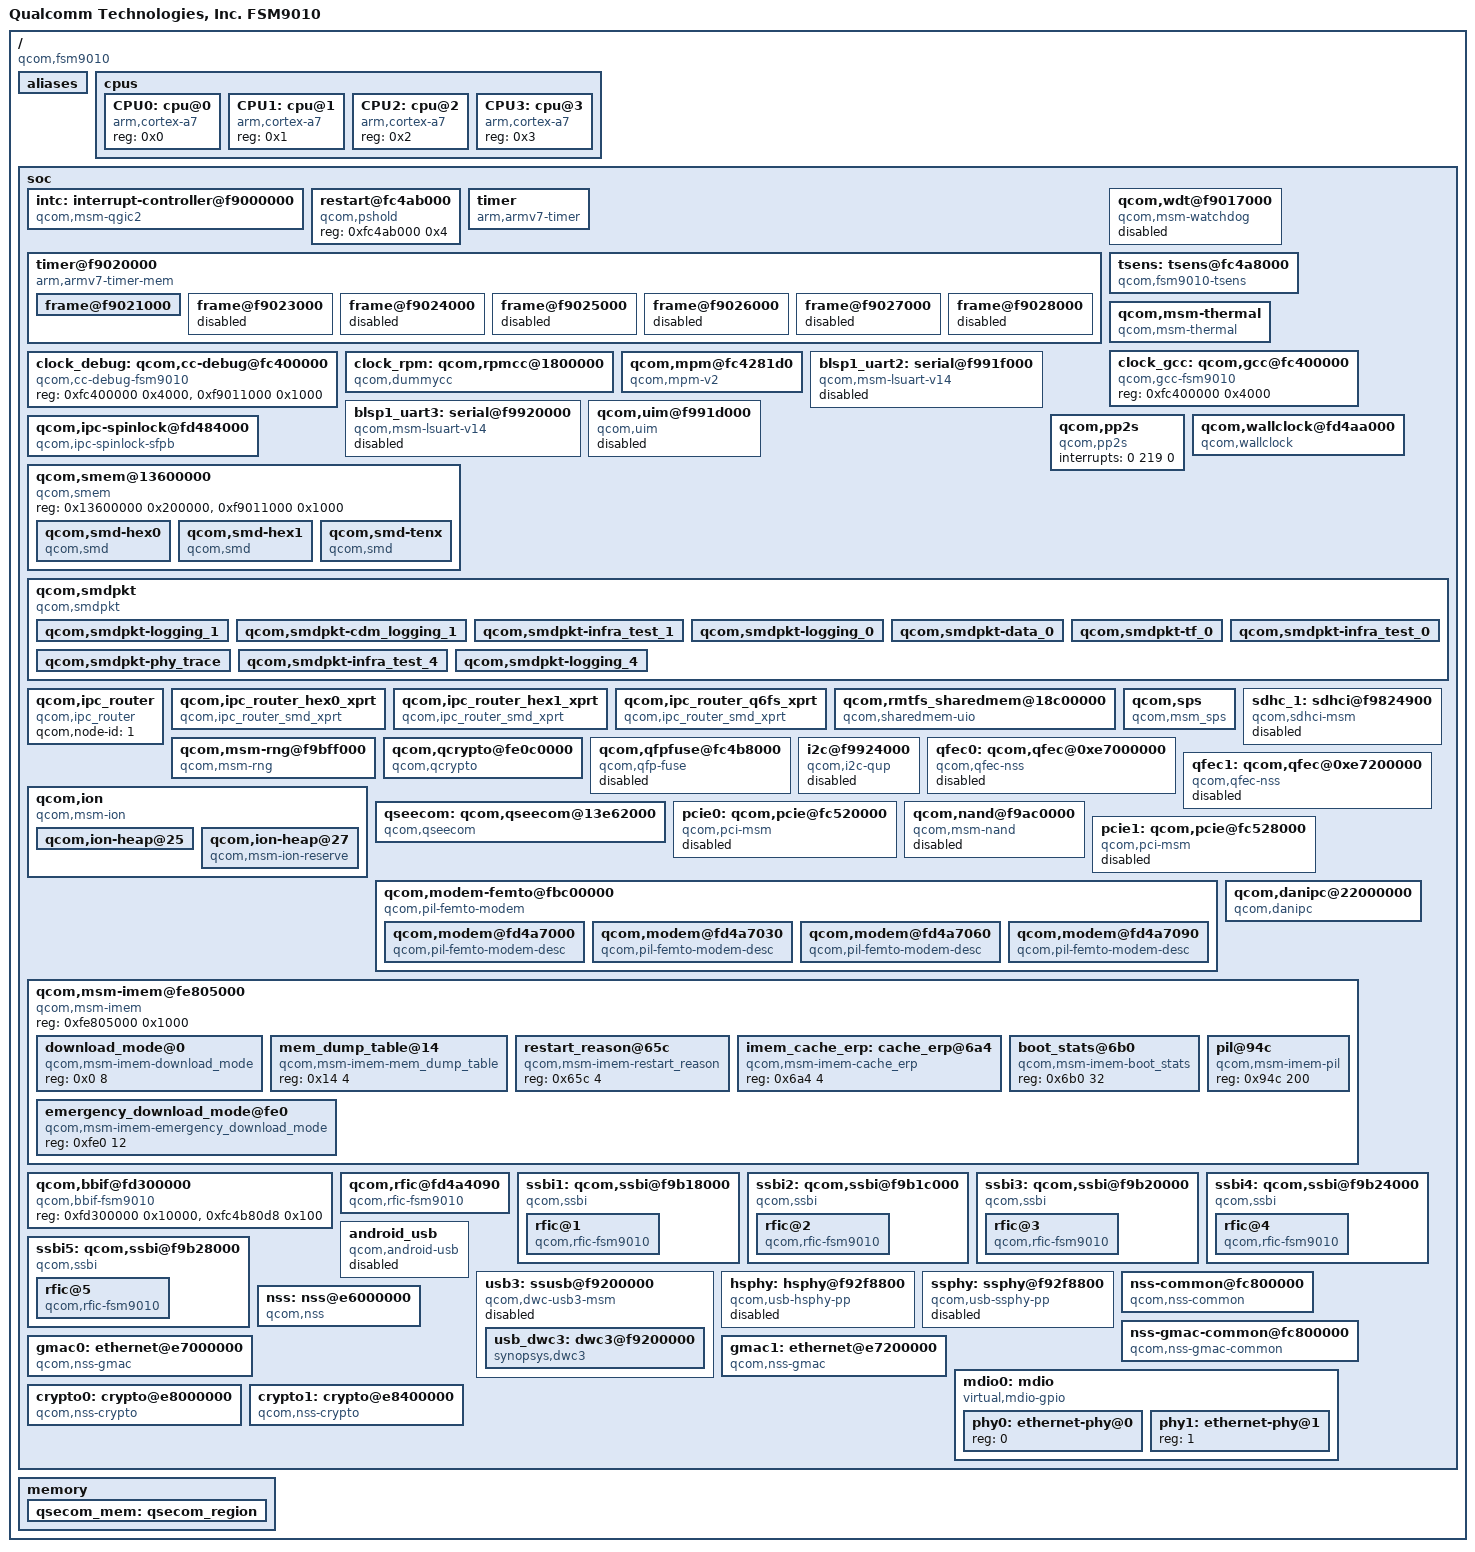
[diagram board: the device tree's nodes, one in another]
/* Copyright (c) 2014-2015, The Linux Foundation. All rights reserved.
 *
 * This program is free software; you can redistribute it and/or modify
 * it under the terms of the GNU General Public License version 2 and
 * only version 2 as published by the Free Software Foundation.
 *
 * This program is distributed in the hope that it will be useful,
 * but WITHOUT ANY WARRANTY; without even the implied warranty of
 * MERCHANTABILITY or FITNESS FOR A PARTICULAR PURPOSE.  See the
 * GNU General Public License for more details.
 */

#include "skeleton.dtsi"
#include <dt-bindings/clock/fsm-clocks-9010.h>

/ {
	model = "Qualcomm Technologies, Inc. FSM9010";
	compatible = "qcom,fsm9010";
	qcom,msm-id = <254 0>,
		      <255 0>,
		      <256 0>,
		      <257 0>;
	interrupt-parent = <&intc>;

	aliases {
		mdio-gpio0 = &mdio0;
		sdhc1 = &sdhc_1; /* SDC1 eMMC slot */
	};

	cpus {
		#size-cells = <0>;
		#address-cells = <1>;

		CPU0: cpu@0 {
			device_type = "cpu";
			compatible = "arm,cortex-a7";
			reg = <0x0>;
		};

		CPU1: cpu@1 {
			device_type = "cpu";
			compatible = "arm,cortex-a7";
			reg = <0x1>;
		};

		CPU2: cpu@2 {
			device_type = "cpu";
			compatible = "arm,cortex-a7";
			reg = <0x2>;
		};

		CPU3: cpu@3 {
			device_type = "cpu";
			compatible = "arm,cortex-a7";
			reg = <0x3>;
		};
	};

	soc: soc { };

	memory {
		#address-cells = <2>;
		#size-cells = <2>;

		qsecom_mem: qsecom_region {
			linux,contiguous-region;
			reg = <0 0 0 0x600000>;
			label = "qseecom_mem";
		};
	};
};

#include "fsm9010-pinctrl.dtsi"

&soc {
	#address-cells = <1>;
	#size-cells = <1>;
	ranges;

	intc: interrupt-controller@f9000000 {
		compatible = "qcom,msm-qgic2";
		interrupt-controller;
		#interrupt-cells = <3>;
		reg = <0xf9000000 0x1000>,
		      <0xf9002000 0x1000>;
	};

	restart@fc4ab000 {
		compatible = "qcom,pshold";
		reg = <0xfc4ab000 0x4>;
		reg-names = "pshold-base";
	};

	timer {
		compatible = "arm,armv7-timer";
		interrupts = <1 2 0xf08>,
			     <1 3 0xf08>,
			     <1 4 0xf08>,
			     <1 1 0xf08>;
		clock-frequency = <19200000>;
	};

	timer@f9020000 {
		#address-cells = <1>;
		#size-cells = <1>;
		ranges;
		compatible = "arm,armv7-timer-mem";
		reg = <0xf9020000 0x1000>;
		clock-frequency = <19200000>;

		frame@f9021000 {
			frame-number = <0>;
			interrupts = <0 8 0x4>,
				     <0 7 0x4>;
			reg = <0xf9021000 0x1000>,
			      <0xf9022000 0x1000>;
		};

		frame@f9023000 {
			frame-number = <1>;
			interrupts = <0 9 0x4>;
			reg = <0xf9023000 0x1000>;
			status = "disabled";
		};

		frame@f9024000 {
			frame-number = <2>;
			interrupts = <0 10 0x4>;
			reg = <0xf9024000 0x1000>;
			status = "disabled";
		};

		frame@f9025000 {
			frame-number = <3>;
			interrupts = <0 11 0x4>;
			reg = <0xf9025000 0x1000>;
			status = "disabled";
		};

		frame@f9026000 {
			frame-number = <4>;
			interrupts = <0 12 0x4>;
			reg = <0xf9026000 0x1000>;
			status = "disabled";
		};

		frame@f9027000 {
			frame-number = <5>;
			interrupts = <0 13 0x4>;
			reg = <0xf9027000 0x1000>;
			status = "disabled";
		};

		frame@f9028000 {
			frame-number = <6>;
			interrupts = <0 14 0x4>;
			reg = <0xf9028000 0x1000>;
			status = "disabled";
		};
	};

	qcom,wdt@f9017000 {
		compatible = "qcom,msm-watchdog";
		reg = <0xf9017000 0x1000>;
		reg-names = "wdt-base";
		interrupts = <0 3 0>, <0 4 0>;
		qcom,bark-time = <11000>;
		qcom,pet-time = <10000>;
		qcom,ipi-ping;
		status = "disabled";
	};

	tsens: tsens@fc4a8000 {
		compatible = "qcom,fsm9010-tsens";
		reg = <0xfc4a8000 0x2000>,
			<0xfc4bc000 0x1000>;
		reg-names = "tsens_physical", "tsens_eeprom_physical";
		interrupts = <0 184 0>;
		interrupt-names = "tsens-upper-lower";
		qcom,sensors = <3>;
		qcom,slope = <2960 2890 2830>;
		qcom,sensor-id = <0 1 5>;
	};

	qcom,msm-thermal {
		compatible = "qcom,msm-thermal";
		qcom,sensor-id = <0>;
		qcom,poll-ms = <250>;
		qcom,therm-reset-temp = <110>;
		qcom,disable-vdd-mx;
		qcom,disable-vdd-rstr;
		qcom,disable-sensor-info;
		qcom,disable-ocr;
		qcom,disable-psm;
		qcom,disable-gfx-phase-ctrl;
		qcom,disable-cx-phase-ctrl;
		qcom,disable-core-control;
		qcom,disable-freq-mitigation;
	};

	clock_gcc: qcom,gcc@fc400000 {
		compatible = "qcom,gcc-fsm9010";
		reg = <0xfc400000 0x4000>;
		reg-names = "cc_base";
		#clock-cells = <1>;
	};

	clock_debug: qcom,cc-debug@fc400000 {
		compatible = "qcom,cc-debug-fsm9010";
		reg = <0xfc400000 0x4000>,
			<0xf9011000 0x1000>;
		reg-names = "cc_base","meas";
		#clock-cells = <1>;
	};

	clock_rpm: qcom,rpmcc@1800000 {
		compatible = "qcom,dummycc";
		#clock-cells = <1>;
	};

	qcom,mpm@fc4281d0 {
		compatible = "qcom,mpm-v2";
		reg = <0xfc4281d0 0x1000>, /* MSM_RPM_MPM_BASE 4K */
		      <0xf9011008 0x4>;   /* MSM_APCS_GCC_BASE 4K */
		reg-names = "vmpm", "ipc";
		interrupts = <0 171 1>;
		clocks = <&clock_rpm clk_xo_lpm_clk>;
		clock-names = "xo";

		qcom,ipc-bit-offset = <1>;

		qcom,gic-parent = <&intc>;
		qcom,gic-map = <2 216>; /* tsens_upper_lower_int */

		qcom,gpio-parent = <&msm_gpio>;
		qcom,gpio-map =
			<4 5>,
			<7 1>,
			<8 6>,
			<14 11>,
			<15 13>,
			<16 86>,
			<17 88>,
			<42 34>,
			<43 36>,
			<44 44>,
			<45 46>;
	};

	blsp1_uart2: serial@f991f000 {
		compatible = "qcom,msm-lsuart-v14";
		reg = <0xf991f000 0x1000>;
		clocks = <&clock_gcc clk_gcc_blsp1_uart1_apps_clk>,
		<&clock_gcc clk_gcc_blsp1_ahb_clk>;
		clock-names = "core_clk", "iface_clk";
		status = "disabled";
		interrupts = <0 95 0>;
	};

	blsp1_uart3: serial@f9920000 {
		compatible = "qcom,msm-lsuart-v14";
		reg = <0xf9920000 0x1000>;
		clocks = <&clock_gcc clk_gcc_blsp1_uart4_apps_clk>,
		<&clock_gcc clk_gcc_blsp1_ahb_clk>;
		clock-names = "core_clk", "iface_clk";
		pinctrl-names = "default";
		pinctrl-0 = <&hsuart3_active>;
		status = "disabled";
		interrupts = <0 96 0>;
	};

	qcom,uim@f991d000 {
		compatible = "qcom,uim";
		reg = <0xf991d000 0x1000>;
		interrupts = <0 98 0>;
		status = "disabled";
		clocks = <&clock_gcc clk_gcc_blsp1_uart1_apps_clk>,
		<&clock_gcc clk_gcc_blsp1_ahb_clk>,
		<&clock_gcc clk_blsp_sim_clk_src>;
		clock-names = "core_clk", "iface_clk", "sim_clk";
		pinctrl-names = "default";
		pinctrl-0 = <&uim0_present_default &uim0_clk_data_default &uim0_reset_default>;
	};

	qcom,pp2s {
		compatible = "qcom,pp2s";
		interrupts = <0 219 0>;
		interrupt-names = "pp2s_irq";
	};

	qcom,wallclock@fd4aa000 {
		compatible = "qcom,wallclock";
		reg-names = "wallclock_time_bank", "wallclock_cntrl_bank1", "wallclock_cntrl_bank2";
		reg = <0xfd4aa000 0x20>, <0xfd4a9000 0x40>, <0xfd4a3200 0x04>;
	};
	qcom,ipc-spinlock@fd484000 {
		compatible = "qcom,ipc-spinlock-sfpb";
		reg = <0xfd484000 0x1000>;
		qcom,num-locks = <32>;
	};

	qcom,smem@13600000 {
		compatible = "qcom,smem";
		reg = <0x13600000 0x200000>,
			<0xf9011000 0x1000>;
		reg-names = "smem", "irq-reg-base";

		qcom,smd-hex0 {
			compatible = "qcom,smd";
			qcom,smd-edge = <0>;
			qcom,smd-irq-offset = <0x8>;
			qcom,smd-irq-bitmask = <0x100>;
			interrupts = <0 72 1>;
			label = "hex0";
			qcom,not-loadable;
		};

		qcom,smd-hex1 {
			compatible = "qcom,smd";
			qcom,smd-edge = <1>;
			qcom,smd-irq-offset = <0x8>;
			qcom,smd-irq-bitmask = <0x1000>;
			interrupts = <0 68 1>;
			label = "hex1";
			qcom,not-loadable;
		};

		qcom,smd-tenx {
			compatible = "qcom,smd";
			qcom,smd-edge = <10>;
			qcom,smd-irq-offset = <0x8>;
			qcom,smd-irq-bitmask = <0x10>;
			interrupts = <0 26 1>;
			label = "tenx";
			qcom,not-loadable;
		};
	};

	qcom,smdpkt {
		compatible = "qcom,smdpkt";

		qcom,smdpkt-logging_1 {
			qcom,smdpkt-remote = "hex0";
			qcom,smdpkt-port-name = "LOGGING_1";
			qcom,smdpkt-dev-name = "smd_logging_1";
		};

		qcom,smdpkt-cdm_logging_1 {
			qcom,smdpkt-remote = "hex0";
			qcom,smdpkt-port-name = "CDM LOGGING_1";
			qcom,smdpkt-dev-name = "smd_cdm_logging_1";
		};

		qcom,smdpkt-infra_test_1 {
			qcom,smdpkt-remote = "hex0";
			qcom,smdpkt-port-name = "INFRA_TEST_1";
			qcom,smdpkt-dev-name = "smd_infra_test_1";
		};

		qcom,smdpkt-logging_0 {
			qcom,smdpkt-remote = "hex1";
			qcom,smdpkt-port-name = "LOGGING";
			qcom,smdpkt-dev-name = "smd_logging_0";
		};

		qcom,smdpkt-data_0 {
			qcom,smdpkt-remote = "hex1";
			qcom,smdpkt-port-name = "DATA";
			qcom,smdpkt-dev-name = "smd_data_0";
		};

		qcom,smdpkt-tf_0 {
			qcom,smdpkt-remote = "hex1";
			qcom,smdpkt-port-name = "TESTFRAMEWORK";
			qcom,smdpkt-dev-name = "smd_tf_0";
		};

		qcom,smdpkt-infra_test_0 {
			qcom,smdpkt-remote = "hex1";
			qcom,smdpkt-port-name = "INFRA_TEST_0";
			qcom,smdpkt-dev-name = "smd_infra_test_0";
		};

		qcom,smdpkt-phy_trace {
			qcom,smdpkt-remote = "tenx";
			qcom,smdpkt-port-name = "PHY_TRACE";
			qcom,smdpkt-dev-name = "smd_phy_trace";
		};

		qcom,smdpkt-infra_test_4 {
			qcom,smdpkt-remote = "tenx";
			qcom,smdpkt-port-name = "INFRA_TEST_4";
			qcom,smdpkt-dev-name = "smd_infra_test_4";
		};

		qcom,smdpkt-logging_4 {
			qcom,smdpkt-remote = "tenx";
			qcom,smdpkt-port-name = "LOGGING_4";
			qcom,smdpkt-dev-name = "smd_logging_4";
		};
	};

	qcom,ipc_router{
		compatible = "qcom,ipc_router";
		qcom,node-id = <1>;
	};

	qcom,ipc_router_hex0_xprt {
		compatible = "qcom,ipc_router_smd_xprt";
		qcom,ch-name = "IPCRTR";
		qcom,xprt-remote = "hex0";
		qcom,xprt-linkid = <1>;
		qcom,xprt-version = <1>;
		qcom,fragmented-data;
	};

	qcom,ipc_router_hex1_xprt {
		compatible = "qcom,ipc_router_smd_xprt";
		qcom,ch-name = "IPCRTR";
		qcom,xprt-remote = "hex1";
		qcom,xprt-linkid = <1>;
		qcom,xprt-version = <1>;
		qcom,fragmented-data;
	};

	qcom,ipc_router_q6fs_xprt {
		compatible = "qcom,ipc_router_smd_xprt";
		qcom,ch-name = "IPCRTR";
		qcom,xprt-remote = "tenx";
		qcom,xprt-linkid = <1>;
		qcom,xprt-version = <1>;
		qcom,fragmented-data;
	};

	qcom,rmtfs_sharedmem@18c00000 {
		compatible = "qcom,sharedmem-uio";
		reg = <0x18c00000 0x00180000>;
		reg-names = "rmtfs";
		qcom,client-id = <0x00000001>;
	};

	qcom,sps {
		compatible = "qcom,msm_sps";
		qcom,device-type = <3>;
		qcom,pipe-attr-ee;
	};

	sdhc_1: sdhci@f9824900 {
		qcom,bus-width = <8>;
		compatible = "qcom,sdhci-msm";
		reg = <0xf9824900 0x11c>, <0xf9824000 0x800>;
		reg-names = "hc_mem", "core_mem";
		interrupts = <0 123 0>, <0 138 0>;
		interrupt-names = "hc_irq", "pwr_irq";
		qcom,bus-speed-mode = "HS200_1p8v", "DDR_1p8v";
		qcom,cpu-dma-latency-us = <200>;

		qcom,msm-bus,name = "sdhc1";
		qcom,msm-bus,num-cases = <8>;
		qcom,msm-bus,num-paths = <1>;
		qcom,msm-bus,vectors-KBps = <78 512 0 0>, /* No vote */
			<78 512 1600 3200>,    /* 400 KB/s*/
			<78 512 80000 160000>, /* 20 MB/s */
			<78 512 100000 200000>, /* 25 MB/s */
			<78 512 200000 400000>, /* 50 MB/s */
			<78 512 400000 800000>, /* 100 MB/s */
			<78 512 800000 1600000>, /* 200 MB/s */
			<78 512 2048000 4096000>; /* Max. bandwidth */
		qcom,bus-bw-vectors-bps = <0 400000 20000000 25000000 50000000 100000000 200000000 4294967295>;
		clock-names = "iface_clk", "core_clk";
		clocks = <&clock_gcc clk_gcc_sdcc1_ahb_clk>,
		         <&clock_gcc clk_gcc_sdcc1_apps_clk>;

		vdd-supply = <&dummy_vreg>;
		qcom,vdd-voltage-level = <2950000 2950000>;
		qcom,vdd-current-level = <200 500000>;

		vdd-io-supply = <&dummy_vreg>;
		qcom,vdd-io-always-on;
		qcom,vdd-io-voltage-level = <1800000 1800000>;
		qcom,vdd-io-current-level = <200 154000>;

		qcom,clk-rates = <400000 20000000 25000000 50000000 100000000 200000000>;
		qcom,nonremovable;
		status = "disable";
	};

	qcom,msm-rng@f9bff000 {
		compatible = "qcom,msm-rng";
		reg = <0xf9bff000 0x140>;
		qcom,msm-rng-iface-clk;
		clocks = <&clock_gcc clk_gcc_prng_ahb_clk>;
		clock-names = "iface_clk";
	};

	qcom,qcrypto@fe0c0000 {
		compatible = "qcom,qcrypto";
		reg = <0xfe0c0000 0x20000>,
			<0xfe0c4000 0x8000>;
		reg-names = "crypto-base","crypto-bam-base";
		interrupts = <0 109 0>;
		qcom,bam-pipe-pair = <0>;
		qcom,ce-hw-instance = <0>;
		qcom,ce-hw-shared;
		qcom,ce-device = <0>;
		clock-names = "core_clk", "iface_clk", "bus_clk",
				 "core_clk_src";
		clocks = <&clock_gcc clk_gcc_ce1_clk>,
			<&clock_gcc clk_gcc_ce1_ahb_clk>,
			<&clock_gcc clk_gcc_ce1_axi_clk>,
			<&clock_gcc clk_ce1_clk_src>;
	};

	qcom,qfpfuse@fc4b8000 {
		compatible = "qcom,qfp-fuse";
		reg = <0xfc4b8000 0x7000>;
		qcom,blow-status-offset = <0x2048>;
		status = "disabled";
	};

	i2c@f9924000 { /* BLSP-1 QUP-2 */
		cell-index = <0>;
		compatible = "qcom,i2c-qup";
		reg = <0xf9924000 0x500>;
		#address-cells = <1>;
		#size-cells = <0>;
		reg-names = "qup_phys_addr";
		interrupts = <0 97 0>;
		interrupt-names = "qup_err_intr";
		qcom,i2c-bus-freq = <100000>;
		qcom,i2c-src-freq = <19200000>;
		clocks = <&clock_gcc clk_gcc_blsp1_qup2_i2c_apps_clk>,
			 <&clock_gcc clk_gcc_blsp1_ahb_clk>;
		clock-names = "core_clk", "iface_clk";
		qcom,master-id = <86>;
		status = "disabled";
	};

	qfec0: qcom,qfec@0xe7000000 {
		compatible = "qcom,qfec-nss";
		cell-index = <0>;
		reg = <0xe7000000 0x10000>,
			<0xfc800000 0x4000>,
			<0xfc900000 0x100000>,
			<0xfcb00000 0x100000>,
			<0xfd510000 0x4000>;
		reg-names = "qfec_mac",
			"qfec_csr",
			"qfec_qsgmii",
			"qfec_rgmii_csr",
			"tlmm_csr";
		interrupts = <0 242 0>;
		clocks = <&clock_rpm clk_gcc_gmac0_axi_clk>;
		clock-names = "core_clk";
		qcom,qsgmii-pcs-chan = <1>;
		qcom,rgmii-capable;
		status = "disabled";
	};

	qfec1: qcom,qfec@0xe7200000 {
		compatible = "qcom,qfec-nss";
		cell-index = <1>;
		reg = <0xe7200000 0x10000>,
			<0xfc800000 0x4000>,
			<0xfc900000 0x100000>,
			<0xfcb00000 0x100000>;
		reg-names = "qfec_mac",
			"qfec_csr",
			"qfec_qsgmii",
			"qfec_rgmii_csr";
		interrupts = <0 244 0>;
		clocks = <&clock_rpm clk_gcc_gmac1_axi_clk>;
		clock-names = "core_clk";
		qcom,qsgmii-pcs-chan = <2>;
		status = "disabled";
	};

	qcom,ion {
		compatible = "qcom,msm-ion";
		#address-cells = <1>;
		#size-cells = <0>;

		qcom,ion-heap@25 {
			reg = <25>;
			qcom,ion-heap-type = "SYSTEM";
		};

		qcom,ion-heap@27 { /* QSECOM HEAP */
			compatible = "qcom,msm-ion-reserve";
			reg = <27>;
			linux,contiguous-region = <&qsecom_mem>;
			qcom,ion-heap-type = "DMA";
		};
	};

	qseecom: qcom,qseecom@13e62000 {
		compatible = "qcom,qseecom";
		reg = <0x13e62000 0x9e000>;
		reg-names = "secapp-region";
		qcom,disk-encrypt-pipe-pair = <2>;
		qcom,hlos-ce-hw-instance = <1>;
		qcom,qsee-ce-hw-instance = <0>;
		qcom,msm-bus,name = "qseecom-noc";
		qcom,msm-bus,num-cases = <4>;
		qcom,msm-bus,num-paths = <1>;
		qcom,msm-bus,vectors-KBps =
				<55 512 0 0>,
				<55 512 3936000 393600>,
				<55 512 3936000 393600>,
				<55 512 3936000 393600>;
		qcom,ce-opp-freq = <100000000>;
		clock-names = "core_clk", "iface_clk", "bus_clk",
				"core_clk_src";
		clocks = <&clock_gcc clk_gcc_ce1_clk>,
			<&clock_gcc clk_gcc_ce1_ahb_clk>,
			<&clock_gcc clk_gcc_ce1_axi_clk>,
			<&clock_gcc clk_ce1_clk_src>;
	};

	pcie0: qcom,pcie@fc520000 {
		compatible = "qcom,pci-msm";
		cell-index = <0>;
		qcom,ctrl-amt = <1>;

		reg = <0xfc520000 0x2000>,
		      <0xfc526000 0x1000>,
		      <0xff800000 0x0f20>,
		      <0xff800f20 0x100>,
		      <0xff870000 0x1000>,
		      <0xff880000 0x80000>,
		      <0xff900000 0x700000>;

		reg-names = "parf", "phy", "dm_core", "elbi",
				"conf", "io", "bars";

		#address-cells = <0>;
		interrupt-parent = <&pcie0>;
		interrupts = <0 1 2 3 4 5 6 7 8 9 10 11 12>;
		#interrupt-cells = <1>;
		interrupt-map-mask = <0xffffffff>;
		interrupt-map = <0 &intc 0 141 0
				1 &intc 0 142 0
				2 &intc 0 143 0
				3 &intc 0 144 0
				4 &intc 0 145 0
				5 &intc 0 146 0
				6 &intc 0 147 0
				7 &intc 0 148 0
				8 &intc 0 149 0
				9 &intc 0 150 0
				10 &intc 0 151 0
				11 &intc 0 152 0 >;
		interrupt-names = "int_msi", "int_a", "int_b", "int_c", "int_d",
				"int_pls_pme", "int_pme_legacy", "int_pls_err",
				"int_aer_legacy", "int_pls_link_up",
				"int_pls_link_down", "int_bridge_flush_n";

		pinctrl-names = "default";
		pinctrl-0 = <&pcie0_perst_default &pcie0_wake_default>;

		perst-gpio = <&msm_gpio 21 0>;
		wake-gpio = <&msm_gpio 23 0>;

		gdsc-vdd-supply = <&gdsc_pcie_0>;
		vreg-1.8-supply = <&stub_regulator_1p8v>;
		vreg-0.9-supply = <&stub_regulator_1v>;

		clocks = <&clock_gcc clk_gcc_pcie_0_pipe_clk>,
			<&clock_rpm clk_ln_bb_clk>,
			<&clock_gcc clk_gcc_pcie_0_aux_clk>,
			<&clock_gcc clk_gcc_pcie_0_cfg_ahb_clk>,
			<&clock_gcc clk_gcc_pcie_0_mstr_axi_clk>,
			<&clock_gcc clk_gcc_pcie_0_slv_axi_clk>,
			<&clock_gcc clk_pcie_0_phy_ldo>,
			<&clock_gcc clk_gcc_pcie_phy_0_reset>;

		clock-names = "pcie_0_pipe_clk", "pcie_0_ref_clk_src",
				"pcie_0_aux_clk", "pcie_0_cfg_ahb_clk",
				"pcie_0_mstr_axi_clk", "pcie_0_slv_axi_clk",
				"pcie_0_ldo", "pcie_0_phy_reset";
		max-clock-frequency-hz = <125000000>, <0>, <1010000>,
						<0>, <0>, <0>, <0>, <0>;
		qcom,ep-latency = <1000>;
		status = "disabled";
	};

	qcom,nand@f9ac0000 {
		compatible = "qcom,msm-nand";
		reg = <0xf9ac0000 0x1000>,
		      <0xf9ac4000 0x8000>;
		reg-names = "nand_phys",
			    "bam_phys";
		interrupts = <0 24 0>;
		interrupt-names = "bam_irq";
		status = "disabled";
	};

	pcie1: qcom,pcie@fc528000 {
		compatible = "qcom,pci-msm";
		cell-index = <1>;
		qcom,ctrl-amt = <1>;

		reg = <0xfc528000 0x2000>,
		      <0xfc52e000 0x1000>,
		      <0xff000000 0xf20>,
		      <0xff000f20 0x100>,
		      <0xff070000 0x1000>,
		      <0xff080000 0x80000>,
		      <0xff100000 0x700000>;

		reg-names = "parf", "phy", "dm_core", "elbi",
				"conf", "io", "bars";

		#address-cells = <0>;
		interrupt-parent = <&pcie1>;
		interrupts = <0 1 2 3 4 5 6 7 8 9 10 11 12>;
		#interrupt-cells = <1>;
		interrupt-map-mask = <0xffffffff>;
		interrupt-map = <0 &intc 0 81 0
				1 &intc 0 82 0
				2 &intc 0 83 0
				3 &intc 0 84 0
				4 &intc 0 85 0
				5 &intc 0 86 0
				6 &intc 0 87 0
				7 &intc 0 88 0
				8 &intc 0 89 0
				9 &intc 0 90 0
				10 &intc 0 91 0
				11 &intc 0 92 0>;
		interrupt-names = "int_msi", "int_a", "int_b", "int_c", "int_d",
				"int_pls_pme", "int_pme_legacy", "int_pls_err",
				"int_aer_legacy", "int_pls_link_up",
				"int_pls_link_down", "int_bridge_flush_n";

		pinctrl-names = "default";
		pinctrl-0 = <&pcie1_perst_default &pcie1_wake_default>;

		perst-gpio = <&msm_gpio 22 0>;
		wake-gpio = <&msm_gpio 24 0>;

		gdsc-vdd-supply = <&gdsc_pcie_1>;
		vreg-1.8-supply = <&stub_regulator_1p8v>;
		vreg-0.9-supply = <&stub_regulator_1v>;

		clocks = <&clock_gcc clk_gcc_pcie_1_pipe_clk>,
			<&clock_rpm clk_ln_bb_clk>,
			<&clock_gcc clk_gcc_pcie_1_aux_clk>,
			<&clock_gcc clk_gcc_pcie_1_cfg_ahb_clk>,
			<&clock_gcc clk_gcc_pcie_1_mstr_axi_clk>,
			<&clock_gcc clk_gcc_pcie_1_slv_axi_clk>,
			<&clock_gcc clk_pcie_1_phy_ldo>,
			<&clock_gcc clk_gcc_pcie_phy_1_reset>;
		clock-names = "pcie_1_pipe_clk", "pcie_1_ref_clk_src",
				"pcie_1_aux_clk", "pcie_1_cfg_ahb_clk",
				"pcie_1_mstr_axi_clk", "pcie_1_slv_axi_clk",
				"pcie_1_ldo", "pcie_1_phy_reset";
		max-clock-frequency-hz = <125000000>, <0>, <1010000>,
						<0>, <0>, <0>, <0>,  <0>;
		qcom,ep-latency = <1000>;
		status = "disabled";
	};

	qcom,modem-femto@fbc00000 {
		compatible = "qcom,pil-femto-modem";
		#address-cells=<1>;
		#size-cells=<1>;
		ranges;
		reg = <0xfbc00000 0x100>;
		reg-names = "qdsp6_base";
		qcom,firmware-name = "mba";
		qcom,max-num-modems = <4>;

		qcom,modem@fd4a7000 {
			compatible = "qcom,pil-femto-modem-desc";
			reg = <0xfd4a7000 0x20>;
			reg-names = "rmb_base";
			qcom,firmware-name = "mdm0";
			qcom,modem-id = <0>;
			qcom,max-num-images = <1>;
		};

		qcom,modem@fd4a7030 {
			compatible = "qcom,pil-femto-modem-desc";
			reg = <0xfd4a7030 0x20>;
			reg-names = "rmb_base";
			qcom,firmware-name = "mdm1";
			qcom,modem-id = <1>;
			qcom,max-num-images = <1>;
		};

		qcom,modem@fd4a7060 {
			compatible = "qcom,pil-femto-modem-desc";
			reg = <0xfd4a7060 0x20>;
			reg-names = "rmb_base";
			qcom,firmware-name = "mdm2";
			qcom,modem-id = <2>;
			qcom,max-num-images = <1>;
			qcom,pil-skip-entry-check;
		};

		qcom,modem@fd4a7090 {
			compatible = "qcom,pil-femto-modem-desc";
			reg = <0xfd4a7090 0x20>;
			reg-names = "rmb_base";
			qcom,firmware-name = "mdm3";
			qcom,modem-id = <3>;
			qcom,max-num-images = <1>;
			qcom,pil-skip-entry-check;
		};
	};

	qcom,danipc@22000000 {
		compatible = "qcom,danipc";
		reg-names = "ipc_bufs", "agent_table", "apps_ipc_intr_en",
			"phycpu0_ipc", "phycpu1_ipc", "phycpu2_ipc",
			"phydsp0_ipc", "phydsp1_ipc", "apps_ipc",
			"qdsp6_0_ipc", "qdsp6_1_ipc";
		reg = <0x22000000 0x80000>, /* ipc_bufs */
			<0x13e60000 0x2000>, /* agent_table */
			<0xfd4a3500 0x100>, /* apps_ipc_intr_en */
			<0xf683a000 0x100>, /* phycpu0_ipc */
			<0xf683a000 0x100>, /* phycpu1_ipc */
			<0xf683c000 0x100>, /* phycpu2_ipc */
			<0xf6862000 0x100>, /* phydsp0_ipc */
			<0xf6862000 0x100>, /* phydsp1_ipc */
			<0xfd490000 0x100>, /* apps_ipc */
			<0xfd495000 0x100>, /* qdsp6_0_ipc */
			<0xfd496000 0x100>; /* qdsp6_1_ipc */
		qcom,qdsp6-1-shm-size = <0x2000000>;
		interrupts = <0 202 0>;
	};

	qcom,msm-imem@fe805000 {
		compatible = "qcom,msm-imem";
		reg = <0xfe805000 0x1000>; /* Address and size of IMEM */
		ranges = <0x0 0xfe805000 0x1000>;
		#address-cells = <1>;
		#size-cells = <1>;

		download_mode@0 {
			compatible = "qcom,msm-imem-download_mode";
			reg = <0x0 8>;
		};

		mem_dump_table@14 {
			compatible = "qcom,msm-imem-mem_dump_table";
			reg = <0x14 4>;
		};

		restart_reason@65c {
			compatible = "qcom,msm-imem-restart_reason";
			reg = <0x65c 4>;
		};

		imem_cache_erp: cache_erp@6a4 {
			compatible = "qcom,msm-imem-cache_erp";
			reg = <0x6a4 4>;
		};

		boot_stats@6b0 {
			compatible = "qcom,msm-imem-boot_stats";
			reg = <0x6b0 32>;
		};

		pil@94c {
			compatible = "qcom,msm-imem-pil";
			reg = <0x94c 200>;
		};

		emergency_download_mode@fe0 {
			compatible = "qcom,msm-imem-emergency_download_mode";
			reg = <0xfe0 12>;
		};
	};

	qcom,bbif@fd300000 {
		compatible = "qcom,bbif-fsm9010";
		reg = <0xfd300000 0x10000>,
			<0xfc4b80d8 0x100>;
	};

	qcom,rfic@fd4a4090 {
		compatible = "qcom,rfic-fsm9010";
		reg = <0xfd4a4090 0x40>,
			<0x29000000 0xa00000>,
			<0xf9b10000 0x8000>,
			<0xfd510000 0x4000>;
		clocks = <&clock_gcc clk_gcc_pdm2_clk>,
			<&clock_gcc clk_gcc_pdm2_ahb_clk>;
		clock-names = "pdm2_clk", "ahb_clk";
		pinctrl-names = "default";
		pinctrl-0 = <&rf_ssbi_default &grfc_f2_default &grfc_f3_default
			&grfc_f4_default &grfc_f5_default &grfc_f6_default
			&grfc_f7_default &pdm_f2_default>;
	};

	ssbi1:  qcom,ssbi@f9b18000 {
		compatible = "qcom,ssbi";
		reg = <0xf9b18000 0x4000>;
		reg-names = "ssbi1_base";
		qcom,controller-type = "geni-ssbi-arbiter";

		rfic@1 {
			compatible = "qcom,rfic-fsm9010";
		};
	};

	ssbi2:  qcom,ssbi@f9b1c000 {
		compatible = "qcom,ssbi";
		reg = <0xf9b1c000 0x4000>;
		reg-names = "ssbi2_base";
		qcom,controller-type = "geni-ssbi-arbiter";

		rfic@2 {
			compatible = "qcom,rfic-fsm9010";
		};
	};

	ssbi3:  qcom,ssbi@f9b20000 {
		compatible = "qcom,ssbi";
		reg = <0xf9b20000 0x4000>;
		reg-names = "ssbi3_base";
		qcom,controller-type = "geni-ssbi-arbiter";

		rfic@3 {
			compatible = "qcom,rfic-fsm9010";
		};
	};

	ssbi4:  qcom,ssbi@f9b24000 {
		compatible = "qcom,ssbi";
		reg = <0xf9b24000 0x4000>;
		reg-names = "ssbi4_base";
		qcom,controller-type = "geni-ssbi-arbiter";

		rfic@4 {
			compatible = "qcom,rfic-fsm9010";
		};
	};

	ssbi5:  qcom,ssbi@f9b28000 {
		compatible = "qcom,ssbi";
		reg = <0xf9b28000 0x4000>;
		reg-names = "ssbi5_base";
		qcom,controller-type = "geni-ssbi-arbiter";

		rfic@5 {
			compatible = "qcom,rfic-fsm9010";
		};
	};

	android_usb {
		compatible = "qcom,android-usb";
		status = "disable";
	};

	usb3: ssusb@f9200000 {
		compatible = "qcom,dwc-usb3-msm";
		reg = <0xf9200000 0xfc000>;
		#address-cells = <1>;
		#size-cells = <1>;
		ranges;
		interrupts = <0 228 0>, <0 226 0>;
		interrupt-names = "hs_phy_irq", "pwr_event_irq";

		qcom,dwc-usb3-msm-tx-fifo-size = <29696>;
		qcom,dwc-usb3-msm-qdss-tx-fifo-size = <8192>;
		vdda33-supply = <&stub_regulator_3p3v>;
		vdda18-supply = <&stub_regulator_1p8v>;

		clocks = <&clock_gcc clk_gcc_usb30_master_clk>,
			 <&clock_gcc clk_gcc_sys_noc_usb3_axi_clk>,
			 <&clock_gcc clk_gcc_usb30_mock_utmi_clk>,
			 <&clock_gcc clk_gcc_usb30_sleep_clk>,
			 <&clock_rpm clk_ln_bb_clk>,
			 <&clock_rpm clk_cxo_dwc3_clk>;
		clock-names = "core_clk", "iface_clk", "utmi_clk", "sleep_clk",
                         "ref_clk", "xo";
		status = "disable";

		usb_dwc3: dwc3@f9200000 {
			compatible = "synopsys,dwc3";
			reg = <0xf9200000 0xf8000>;
			interrupt-parent = <&intc>;
			interrupts = <0 224 0>, <0 225 0>;
			interrupt-names = "irq", "otg_irq";
			usb-phy = <&hsphy>, <&ssphy>;
			maximum-speed = "super-speed";
			snps,nominal-elastic-buffer;
			snps,hird_thresh = <0x10>;
			snps,usb3-u1u2-disable;
		};
	};


	hsphy:  hsphy@f92f8800 {
		compatible = "qcom,usb-hsphy-pp";
		reg = <0xfca00000 0x200>,
		      <0xf92f8800 0x3ff>;
		reg-names = "hsphy_base",
			     "qscratch_phy";
		qcom,hsphy-init = <0x031188C4>;
		vdd-supply = <&stub_regulator_vdd_mx>;
		vdda18-supply = <&stub_regulator_1p8v>;
		vdda33-supply = <&stub_regulator_3p3v>;
		qcom,vdd-voltage-level = <1 5 7>;
		qcom,ext-vbus-id;
		qcom,vbus-valid-override;
		qcom,vdda-force-on;
		status = "disable";
	};

	ssphy: ssphy@f92f8800   {
		compatible = "qcom,usb-ssphy-pp";
		reg = <0xfca01000 0xAC>,
		      <0xf92f8800 0x3ff>;
		reg-names = "ssphy_base",
			     "qscratch_phy";
		vdd-supply = <&stub_regulator_vdd_mx>;
		vdda18-supply =  <&stub_regulator_1p8v>;
		qcom,vdd-voltage-level = <1 5 7>;
		qcom,ext-vbus-id;
		clocks = <&clock_gcc clk_gcc_usb3_phy_reset>,
			 <&clock_gcc clk_gcc_usb3phy_phy_reset>;
		clock-names = "phy_reset", "phy_phy_reset";
		status = "disable";
	};

	nss-common@fc800000 {
		compatible = "qcom,nss-common";
		reg-names = "nss_fpb_base", "clk_ctl_base";
		reg = <0xfc800000 0x00001000>,
		      <0xfc400000 0x00004000>;
	};

	nss: nss@e6000000 {
		compatible = "qcom,nss";
		interrupts = <0 229 0x4>,
			     <0 230 0x4>;
		reg-names = "nphys", "vphys";
		reg = <0xe6000000 0x1000>,
		      <0xe4000000 0x20000>;
		qcom,id = <0>;
		qcom,nss-ctrl = <1>;
		qcom,ipv4-enabled;
		qcom,ipv6-enabled;
		qcom,crypto-enabled;
		qcom,gmac0-enabled;
		qcom,gmac1-enabled;
	};

	nss-gmac-common@fc800000 {
		compatible = "qcom,nss-gmac-common";
		reg-names = "nss_reg_base" , "qsgmii_reg_base", "clk_ctl_base";
		reg = <0xfc800000 0x0000ffff>,
		      <0xfc900000 0x0000ffff>,
		      <0xfc400000 0x00004000>;
	};

	gmac0: ethernet@e7000000 {
		device_type = "network";
		compatible = "qcom,nss-gmac";
		reg = <0xe7000000 0x200000>;
		interrupts = <0 242 0>;
		phy-mode = "sgmii";
		qcom,id = <0>;
		qcom,pcs-chanid = <1>;
		qcom,phy-mdio-addr = <0>;
		qcom,poll-required = <1>;
		qcom,rgmii-delay = <0>;
		qcom,forced-speed = <0>;
		qcom,forced-duplex = <10>;
		local-mac-address = [000000000000];
		mdiobus = <&mdio0>;
	};

	gmac1: ethernet@e7200000 {
		device_type = "network";
		compatible = "qcom,nss-gmac";
		reg = <0xe7200000 0x200000>;
		interrupts = <0 244 0>;
		phy-mode = "sgmii";
		qcom,id = <1>;
		qcom,pcs-chanid = <2>;
		qcom,phy-mdio-addr = <1>;
		qcom,poll-required = <1>;
		qcom,rgmii-delay = <0>;
		qcom,forced-speed = <0>;
		qcom,forced-duplex = <10>;
		local-mac-address = [000000000000];
		mdiobus = <&mdio0>;
	};

	mdio0: mdio {
		compatible = "virtual,mdio-gpio";
		#address-cells = <1>;
		#size-cells = <0>;

		pinctrl-names = "default";
		pinctrl-0 = <&mdc0_pin_default &mdio0_pin_default>;

		gpios = <&msm_gpio 14 0 &msm_gpio 15 0>;

		phy0: ethernet-phy@0 {
			device_type = "ethernet-phy";
			reg = <0>;
		};
		phy1: ethernet-phy@1 {
			device_type = "ethernet-phy";
			reg = <1>;
		};
	};

	crypto0: crypto@e8000000 {
		compatible = "qcom,nss-crypto";
		reg-names = "crypto_pbase", "bam_base";
		reg = <0xe8000000 0x20000>,
			<0xe8004000 0x22000>;
		qcom,ee = <0>;
	};

	crypto1: crypto@e8400000 {
		compatible = "qcom,nss-crypto";
		reg-names = "crypto_pbase", "bam_base";
		reg = <0xe8400000 0x20000>,
			<0xe8404000 0x22000>;
		qcom,ee = <0>;
	};
};

#include "fsm9010-regulator.dtsi"
